# ATmega16 device description
Architecture: AVR8; Family: megaAVR
Registers are 8-bit, access not given, no defined reset value unless marked. A register's access mark holds for its fields unless they carry their own. Offsets are from the block's base; [hi:lo] are bit positions; 'fields as' and 'values as' point back to an identical list.

## EEPROM
Instances: EEPROM 0x00
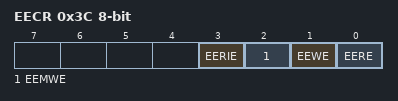
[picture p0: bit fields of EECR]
0x3C EECR — EEPROM Control Register
  [3] EERIE — EEPROM Ready Interrupt Enable
  [2] EEMWE — EEPROM Master Write Enable
  [1] EEWE — EEPROM Write Enable
  [0] EERE — EEPROM Read Enable
0x3D EEDR — EEPROM Data Register
0x3E EEAR 16-bit bits used 8:0 — EEPROM Address Register Bytes

## CPU — CPU Registers
Instances: CPU 0x00
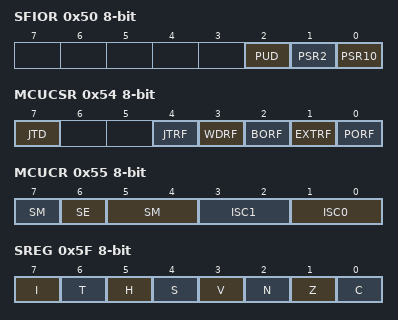
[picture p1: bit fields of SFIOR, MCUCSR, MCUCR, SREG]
0x50 SFIOR — Special function I/O register
  [2] PUD — Pull-up Disable
  [1] PSR2 — Prescaler reset
  [0] PSR10 — Prescaler reset
0x51 OSCCAL — Oscillator Calibration Value
  [7:0] OSCCAL — Oscillator Calibration
0x54 MCUCSR — MCU Control And Status Register
  [7] JTD — JTAG Interface Disable
  [4] JTRF — JTAG Reset Flag
  [3] WDRF — Watchdog Reset Flag
  [2] BORF — Brown-out Reset Flag
  [1] EXTRF — External Reset Flag
  [0] PORF — Power-on reset flag
0x55 MCUCR — MCU Control Register
  [6] SE — Sleep Enable
  [7,5:4] SM — Sleep Mode Select
    0=IDLE; 1=ADC (ADC Noise Reduction (If Available)); 2=PDOWN (Power Down); 3=PSAVE (Power Save); 10=STDBY (Standby); 11=ESTDBY (Extended Standby)
  [3:2] ISC1 — Interrupt Sense Control 1 Bits
    0=LOW_LEVEL_OF_INTX; 1=ANY_LOGICAL_CHANGE_IN_INTX; 2=FALLING_EDGE_OF_INTX; 3=RISING_EDGE_OF_INTX
  [1:0] ISC0 — Interrupt Sense Control 0 Bits
    values as ISC1
0x5D SP 16-bit — Stack Pointer
0x5F SREG — Status Register
  [7] I — Global Interrupt Enable
  [6] T — Bit Copy Storage
  [5] H — Half Carry Flag
  [4] S — Sign Bit
  [3] V — Two's Complement Overflow Flag
  [2] N — Negative Flag
  [1] Z — Zero Flag
  [0] C — Carry Flag
Value list OSCCAL_VALUE_ADDRESSES: 0=1_0_MHz; 1=2_0_MHz; 2=4_0_MHz; 3=8_0_MHz

## TC2 (TC8_ASYNC module) — Timer/Counter, 8-bit Async
Instances: TC2 0x00
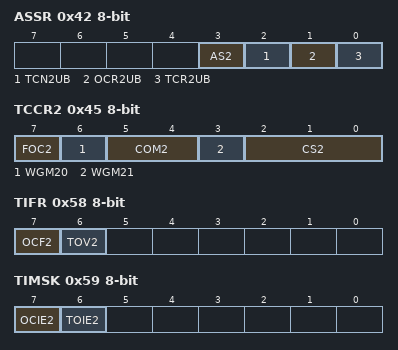
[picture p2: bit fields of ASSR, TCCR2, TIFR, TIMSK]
0x42 ASSR — Asynchronous Status Register
  [3] AS2 — Asynchronous Timer/counter2
  [2] TCN2UB — Timer/Counter2 Update Busy
  [1] OCR2UB — Output Compare Register2 Update Busy
  [0] TCR2UB — Timer/counter Control Register2 Update Busy
0x43 OCR2 — Timer/Counter2 Output Compare Register
0x44 TCNT2 — Timer/Counter2
0x45 TCCR2 — Timer/Counter2 Control Register
  [7] FOC2 — Force Output Compare
  [6] WGM20 — Waveform Generation Mode
    0=NORMAL; 2=PWM_PHASE_CORRECT; 1=CTC; 3=FAST_PWM
  [5:4] COM2 — Compare Output Mode bits
  [3] WGM21 — Waveform Generation Mode
  [2:0] CS2 — Clock Select bits
    0=NO_CLOCK_SOURCE_STOPPED; 1=RUNNING_NO_PRESCALING; 2=RUNNING_CLK_8; 3=RUNNING_CLK_32; 4=RUNNING_CLK_64; 5=RUNNING_CLK_128; 6=RUNNING_CLK_256; 7=RUNNING_CLK_1024
0x50 SFIOR — Special Function IO Register
  [1] PSR2 — Prescaler Reset Timer/Counter2
0x58 TIFR — Timer/Counter Interrupt Flag Register
  [7] OCF2 — Output Compare Flag 2
  [6] TOV2 — Timer/Counter2 Overflow Flag
0x59 TIMSK — Timer/Counter Interrupt Mask register
  [7] OCIE2 — Timer/Counter2 Output Compare Match Interrupt Enable
  [6] TOIE2 — Timer/Counter2 Overflow Interrupt Enable

## SPI — Serial Peripheral Interface
Instances: SPI 0x00
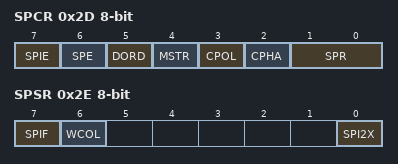
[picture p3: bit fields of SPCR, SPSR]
0x2D SPCR — SPI Control Register
  [7] SPIE — SPI Interrupt Enable
  [6] SPE — SPI Enable
  [5] DORD — Data Order
  [4] MSTR — Master/Slave Select
  [3] CPOL — Clock polarity
  [2] CPHA — Clock Phase
  [1:0] SPR — SPI Clock Rate Selects
    0=FOSC_4; 1=FOSC_16; 2=FOSC_64; 3=FOSC_128; 4=FOSC_2; 5=FOSC_8; 6=FOSC_32; 7=FOSC_64
0x2E SPSR — SPI Status Register
  [7] SPIF — SPI Interrupt Flag
  [6] WCOL — Write Collision Flag
  [0] SPI2X — Double SPI Speed Bit
0x2F SPDR — SPI Data Register

## USART
Instances: USART 0x00
0x29 UBRRL — USART Baud Rate Register Low Byte
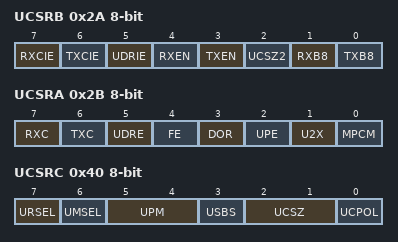
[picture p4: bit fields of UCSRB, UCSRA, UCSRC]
0x2A UCSRB — USART Control and Status Register B
  [7] RXCIE — RX Complete Interrupt Enable
  [6] TXCIE — TX Complete Interrupt Enable
  [5] UDRIE — USART Data register Empty Interrupt Enable
  [4] RXEN — Receiver Enable
  [3] TXEN — Transmitter Enable
  [2] UCSZ2 — Character Size
  [1] RXB8 — Receive Data Bit 8
  [0] TXB8 — Transmit Data Bit 8
0x2B UCSRA — USART Control and Status Register A
  [7] RXC — USART Receive Complete
  [6] TXC — USART Transmit Complete
  [5] UDRE — USART Data Register Empty
  [4] FE — Framing Error
  [3] DOR — Data overRun
  [2] UPE — Parity Error
  [1] U2X — Double the USART transmission speed
  [0] MPCM — Multi-processor Communication Mode
0x2C UDR — USART I/O Data Register
0x40 UCSRC — USART Control and Status Register C
  [7] URSEL — Register Select
  [6] UMSEL — USART Mode Select
    0=ASYNCHRONOUS_OPERATION; 1=SYNCHRONOUS_OPERATION
  [5:4] UPM — Parity Mode Bits
    0=DISABLED; 2=ENABLED_EVEN_PARITY; 3=ENABLED_ODD_PARITY
  [3] USBS — Stop Bit Select
    0=1_BIT; 1=2_BIT
  [2:1] UCSZ — Character Size
  [0] UCPOL — Clock Polarity
0x40 UBRRH bits used 3:0 — USART Baud Rate Register High Byte
